AUTOSAR XML (schema 4-1-3)
standard types defined: boolean, sint8, uint16, uint32, uint8, boolean_CompuMethod, boolean_DataConstr, sint8_DataConstr, uint16_DataConstr, uint32_DataConstr, uint8_DataConstr, sint16
package /MICROSAR/Dem_swc/DataTypes
  5 x impl type:
    Dem_DebounceResetStatusType: compu {0=DEM_DEBOUNCE_STATUS_FREEZE, 1=DEM_DEBOUNCE_STATUS_RESET}, range raw 0..255, implementation-data-type=ImplementationDataTypes/uint8
    Dem_DTCFormatType: compu {0=DEM_DTC_FORMAT_OBD, 1=DEM_DTC_FORMAT_UDS, 2=DEM_DTC_FORMAT_J1939}, range raw 0..2, implementation-data-type=ImplementationDataTypes/uint8
    Dem_EventStatusType:
      compu {0=DEM_EVENT_STATUS_PASSED, 1=DEM_EVENT_STATUS_FAILED, 2=DEM_EVENT_STATUS_PREPASSED, 3=DEM_EVENT_STATUS_PREFAILED, 4=DEM_EVENT_STATUS_FDC_THRESHOLD_REACHED, 5=DEM_EVENT_STATUS_PASSED_CONDITIONS_NOT_FULFILLED, 6=DEM_EVENT_STATUS_FAILED_CONDITIONS_NOT_FULFILLED, 7=DEM_EVENT_STATUS_PREPASSED_CONDITIONS_NOT_FULFILLED, 8=DEM_EVENT_STATUS_PREFAILED_CONDITIONS_NOT_FULFILLED}
      range raw 0..255
      implementation-data-type=ImplementationDataTypes/uint8
    Dem_MaxDataValueType: category=ARRAY, sw-calibration-access=READ-ONLY
      element Dem_MaxDataValueTypeElement: array-size=40, array-size-semantics=FIXED-SIZE, implementation-data-type=ImplementationDataTypes/uint8
    Dem_UdsStatusByteType:
      compu {mask 1: 1=DEM_UDS_STATUS_TF (bit 0: TestFailed), mask 2: 2=DEM_UDS_STATUS_TFTOC (bit 1: TestFailedThisOperationCycle), mask 4: 4=DEM_UDS_STATUS_PDTC (bit 2: PendingDTC), mask 8: 8=DEM_UDS_STATUS_CDTC (bit 3: ConfirmedDTC), mask 16: 16=DEM_UDS_STATUS_TNCSLC (bit 4: TestNotCompletedSinceLastClear), mask 32: 32=DEM_UDS_STATUS_TFSLC (bit 5: TestFailedSinceLastClear), mask 64: 64=DEM_UDS_STATUS_TNCTOC (bit 6: TestNotCompletedThisOperationCycle), mask 128: 128=DEM_UDS_STATUS_WIR (bit 7: WarningIndicatorRequested)}
      range raw 0..255
      implementation-data-type=ImplementationDataTypes/uint8
package /MICROSAR/Dem_swc/Interfaces
  client server interface DiagnosticMonitor: is-service=true, service-kind=DIAGNOSTIC-EVENT-MANAGER
    11 x operation:
      GetDTCOfEvent: possible-error=[DEM_E_NO_DTC_AVAILABLE, DiagnosticMonitor/E_NOT_OK]
        arg DTCFormat: type=Dem_DTCFormatType, direction=IN, server-argument-impl-policy=USE-ARGUMENT-TYPE
        arg DTCOfEvent: type=ImplementationDataTypes/uint32, direction=OUT, server-argument-impl-policy=USE-ARGUMENT-TYPE
      GetEventExtendedDataRecordEx: possible-error=[DEM_BUFFER_TOO_SMALL, DEM_NO_SUCH_ELEMENT, DiagnosticMonitor/E_NOT_OK]
        arg RecordNumber: type=ImplementationDataTypes/uint8, direction=IN, server-argument-impl-policy=USE-ARGUMENT-TYPE
        arg DestBuffer: type=Dem_MaxDataValueType, direction=OUT, server-argument-impl-policy=USE-ARGUMENT-TYPE
        arg BufSize: type=ImplementationDataTypes/uint16, direction=INOUT, server-argument-impl-policy=USE-ARGUMENT-TYPE
      GetEventFailed: possible-error=DiagnosticMonitor/E_NOT_OK
        arg EventFailed: type=ImplementationDataTypes/boolean, direction=OUT, server-argument-impl-policy=USE-ARGUMENT-TYPE
      GetEventFreezeFrameDataEx: possible-error=[DEM_BUFFER_TOO_SMALL, DEM_NO_SUCH_ELEMENT, DiagnosticMonitor/E_NOT_OK]
        4 x arg, all with server-argument-impl-policy=USE-ARGUMENT-TYPE:
          RecordNumber: type=ImplementationDataTypes/uint8, direction=IN
          DataId: type=ImplementationDataTypes/uint16, direction=IN
          DestBuffer: type=Dem_MaxDataValueType, direction=OUT
          BufSize: type=ImplementationDataTypes/uint16, direction=INOUT
      GetEventStatus: possible-error=DiagnosticMonitor/E_NOT_OK
        arg UDSStatusByte: type=Dem_UdsStatusByteType, direction=OUT, server-argument-impl-policy=USE-ARGUMENT-TYPE
      GetEventTested: possible-error=DiagnosticMonitor/E_NOT_OK
        arg EventTested: type=ImplementationDataTypes/boolean, direction=OUT, server-argument-impl-policy=USE-ARGUMENT-TYPE
      GetEventUdsStatus: possible-error=DiagnosticMonitor/E_NOT_OK
        arg UDSStatusByte: type=Dem_UdsStatusByteType, direction=OUT, server-argument-impl-policy=USE-ARGUMENT-TYPE
      GetFaultDetectionCounter: possible-error=[DEM_E_NO_FDC_AVAILABLE, DiagnosticMonitor/E_NOT_OK]
        arg FaultDetectionCounter: type=sint8, direction=OUT, server-argument-impl-policy=USE-ARGUMENT-TYPE
      ResetEventDebounceStatus: possible-error=DiagnosticMonitor/E_NOT_OK
        arg DebounceResetStatus: type=Dem_DebounceResetStatusType, direction=IN, server-argument-impl-policy=USE-ARGUMENT-TYPE
      ResetEventStatus: possible-error=DiagnosticMonitor/E_NOT_OK
      SetEventStatus: possible-error=DiagnosticMonitor/E_NOT_OK
        arg EventStatus: type=Dem_EventStatusType, direction=IN, server-argument-impl-policy=USE-ARGUMENT-TYPE
    5 x error:
      DEM_BUFFER_TOO_SMALL: error-code=21
      DEM_E_NO_DTC_AVAILABLE: error-code=10
      DEM_E_NO_FDC_AVAILABLE: error-code=14
      DEM_NO_SUCH_ELEMENT: error-code=48
      E_NOT_OK: error-code=1
package /UAES/ASW/ApplicationDataTypes
  app type Perc_q0p0122_Perc_s16: category=VALUE, sw-calibration-access=READ-WRITE, compu {phys=raw*0.01220703125 for raw -INF..INF; unit %}, range raw -32768..32767
  app type Ti_q0p001_s_u16: category=VALUE, sw-calibration-access=READ-WRITE, compu {phys=raw*0.001}, range phys 0..65.535
  app type Ti_q1_us_u32: category=VALUE, sw-calibration-access=READ-WRITE, compu {phys=raw for raw -INF..INF; unit us}, range phys 0..4294967295, raw 0..4294967295
package /UAES/ASW/CompuMethods
  compu method CM_boolean: 0=FALSE, 1=TRUE
package /UAES/ASW/DataConstrs
  range DC_boolean: raw 0..1
  range DC_sint16: raw -32768..32767
  range DC_uint16: phys 0..6553.5, raw 0..65535
  range DC_uint32: raw 0..4294967295
  range DC_uint8: raw 0..255
package /UAES/ASW/DataTypeMappingSets
  data type mapping set DTMS_ChrgPlgLock_VD
    data-type-maps:
      application-data-type=Perc_q0p0122_Perc_s16, implementation-data-type=sint16
      application-data-type=Ti_q0p001_s_u16, implementation-data-type=ImplementationDataTypes/uint16
      application-data-type=Ti_q1_us_u32, implementation-data-type=ImplementationDataTypes/uint32
package /UAES/ASW/ImplementationDataTypes/Ground
  11 x constant specification:
    ChgrPlug_cntrTryClsng_C: value-spec=ChgrPlug_cntrTryClsng_C:10
    ChgrPlug_cntrTryOpng_C: value-spec=ChgrPlug_cntrTryOpng_C:10
    ChgrPlug_flgLockActrErr_C: value-spec=ChgrPlug_flgLockActrErr_C:0
    ChgrPlug_ratPlgLockClsng_C: value-spec=100 %
    ChgrPlug_ratPlgLockOff_C: value-spec=0 %
    ChgrPlug_ratPlgLockOpng_C: value-spec=-100 %
    ChgrPlug_tiPlgLockClsng_C: value-spec=0.5
    ChgrPlug_tiPlgLockOff_C: value-spec=0.1
    ChgrPlug_tiPlgLockOpng_C: value-spec=0.5
    ChgrPlug_tiPlgLockPwrOn_C: value-spec=0.5
    IntlckChrgPlg_tiActrPerd_C: value-spec=5000 us
package /UAES/ASW/PortInterfaces
  client server interface IoHwAb_HbrModCtrl
    operation Hbr_SetMod: possible-error=IoHwAb_HbrModCtrl/E_NOT_OK
      arg id_u16: type=ImplementationDataTypes/uint16, direction=IN, server-argument-impl-policy=USE-ARGUMENT-TYPE
      arg mod_u8: type=ImplementationDataTypes/uint8, direction=IN, server-argument-impl-policy=USE-ARGUMENT-TYPE
    error E_NOT_OK: error-code=1
  client server interface IoHwAb_HbrPwm
    operation Hbr_SetDuty: possible-error=IoHwAb_HbrPwm/E_NOT_OK
      arg id_u16: type=ImplementationDataTypes/uint16, direction=IN, server-argument-impl-policy=USE-ARGUMENT-TYPE
      arg duty_u16: type=ImplementationDataTypes/uint16, direction=IN, server-argument-impl-policy=USE-ARGUMENT-TYPE
    operation Hbr_SetPerd: possible-error=IoHwAb_HbrPwm/E_NOT_OK
      arg id_u16: type=ImplementationDataTypes/uint16, direction=IN, server-argument-impl-policy=USE-ARGUMENT-TYPE
      arg perd_u32: type=ImplementationDataTypes/uint32, direction=IN, server-argument-impl-policy=USE-ARGUMENT-TYPE
    operation Hbr_SetPerdAndDuty: possible-error=IoHwAb_HbrPwm/E_NOT_OK
      arg id_u16: type=ImplementationDataTypes/uint16, direction=IN, server-argument-impl-policy=USE-ARGUMENT-TYPE
      arg perd_u32: type=ImplementationDataTypes/uint32, direction=IN, server-argument-impl-policy=USE-ARGUMENT-TYPE
      arg duty_u16: type=ImplementationDataTypes/uint16, direction=IN, server-argument-impl-policy=USE-ARGUMENT-TYPE
    error E_NOT_OK: error-code=1
  client server interface IoHwAb_IoDiagHbr
    operation Hbr_Get: possible-error=IoHwAb_IoDiagHbr/E_NOT_OK
      arg id_u16: type=ImplementationDataTypes/uint16, direction=IN, server-argument-impl-policy=USE-ARGUMENT-TYPE
      arg val_u32: type=ImplementationDataTypes/uint32, direction=OUT, server-argument-impl-policy=USE-ARGUMENT-TYPE
    error E_NOT_OK: error-code=1
  8 x sender receiver interface:
    BattU_bVoltEnbPinDiag: invalidation-policy{data-element=BattU_bVoltEnbPinDiag/Val, handle-invalid=DONT-INVALIDATE}
      data Val: sw-calibration-access=READ-ONLY, type=ImplementationDataTypes/boolean
    ChgrPlug_stPlgLock: invalidation-policy{data-element=ChgrPlug_stPlgLock/Val, handle-invalid=DONT-INVALIDATE}
      data Val: sw-calibration-access=READ-ONLY, type=ImplementationDataTypes/uint8
    ChgrPlug_stPlgLockStMac: invalidation-policy{data-element=ChgrPlug_stPlgLockStMac/Val, handle-invalid=DONT-INVALIDATE}
      data Val: sw-calibration-access=READ-ONLY, type=ImplementationDataTypes/uint8
    ChrgPlg_stPlgLockCmd: invalidation-policy{data-element=ChrgPlg_stPlgLockCmd/Val, handle-invalid=DONT-INVALIDATE}
      data Val: sw-calibration-access=READ-ONLY, type=ImplementationDataTypes/uint8
    ChrgPlgPosn_st: invalidation-policy{data-element=ChrgPlgPosn_st/Val, handle-invalid=DONT-INVALIDATE}
      data Val: sw-calibration-access=READ-ONLY, type=ImplementationDataTypes/uint8
    IntlckChrgPlg_rActr: invalidation-policy{data-element=IntlckChrgPlg_rActr/Val, handle-invalid=DONT-INVALIDATE}
      data Val: sw-calibration-access=READ-ONLY, type=Perc_q0p0122_Perc_s16
    IntlckChrgPlg_tiActr: invalidation-policy{data-element=IntlckChrgPlg_tiActr/Val, handle-invalid=DONT-INVALIDATE}
      data Val: sw-calibration-access=READ-ONLY, type=Ti_q1_us_u32
    VehCoorn_stPwrMod: invalidation-policy{data-element=VehCoorn_stPwrMod/Val, handle-invalid=DONT-INVALIDATE}
      data Val: sw-calibration-access=READ-ONLY, type=ImplementationDataTypes/uint8
package /UAES/ASW/SwAddrMethods
  sw addr method CALDATA
package /UAES/ASW/SwComponentTypes
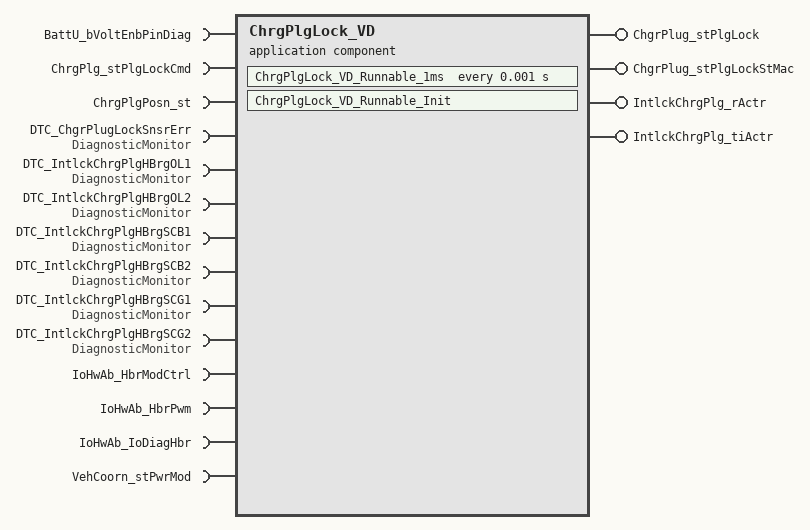
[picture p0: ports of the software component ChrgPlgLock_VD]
  application sw component type ChrgPlgLock_VD
    4 x provide port:
      ChgrPlug_stPlgLock: nonqueued-sender-com-spec{data-element=ChgrPlug_stPlgLock/Val, init-value=0}, provided-interface=ChgrPlug_stPlgLock
      ChgrPlug_stPlgLockStMac: nonqueued-sender-com-spec{data-element=ChgrPlug_stPlgLockStMac/Val, init-value=0}, provided-interface=ChgrPlug_stPlgLockStMac
      IntlckChrgPlg_rActr: nonqueued-sender-com-spec{data-element=IntlckChrgPlg_rActr/Val, init-value=0 %}, provided-interface=IntlckChrgPlg_rActr
      IntlckChrgPlg_tiActr: nonqueued-sender-com-spec{data-element=IntlckChrgPlg_tiActr/Val, init-value=0 us}, provided-interface=IntlckChrgPlg_tiActr
    14 x require port:
      BattU_bVoltEnbPinDiag: nonqueued-receiver-com-spec{data-element=BattU_bVoltEnbPinDiag/Val, filter=data-filter-type=ALWAYS, init-value=0}, required-interface=BattU_bVoltEnbPinDiag
      ChrgPlg_stPlgLockCmd: nonqueued-receiver-com-spec{data-element=ChrgPlg_stPlgLockCmd/Val, filter=data-filter-type=ALWAYS, init-value=0}, required-interface=ChrgPlg_stPlgLockCmd
      ChrgPlgPosn_st: nonqueued-receiver-com-spec{data-element=ChrgPlgPosn_st/Val, filter=data-filter-type=ALWAYS, init-value=0}, required-interface=ChrgPlgPosn_st
      DTC_ChgrPlugLockSnsrErr: required-interface=DiagnosticMonitor
        required-com-specs:
          GetDTCOfEvent
          GetEventExtendedDataRecordEx
          GetEventFailed
          GetEventFreezeFrameDataEx
          GetEventStatus
          GetEventTested
          GetEventUdsStatus
          GetFaultDetectionCounter
          ResetEventDebounceStatus
          ResetEventStatus
          SetEventStatus
      DTC_IntlckChrgPlgHBrgOL1: required-interface=DiagnosticMonitor
        required-com-specs:
          GetDTCOfEvent
          GetEventExtendedDataRecordEx
          GetEventFailed
          GetEventFreezeFrameDataEx
          GetEventStatus
          GetEventTested
          GetEventUdsStatus
          GetFaultDetectionCounter
          ResetEventDebounceStatus
          ResetEventStatus
          SetEventStatus
      DTC_IntlckChrgPlgHBrgOL2: required-interface=DiagnosticMonitor
        required-com-specs:
          GetDTCOfEvent
          GetEventExtendedDataRecordEx
          GetEventFailed
          GetEventFreezeFrameDataEx
          GetEventStatus
          GetEventTested
          GetEventUdsStatus
          GetFaultDetectionCounter
          ResetEventDebounceStatus
          ResetEventStatus
          SetEventStatus
      DTC_IntlckChrgPlgHBrgSCB1: required-interface=DiagnosticMonitor
        required-com-specs:
          GetDTCOfEvent
          GetEventExtendedDataRecordEx
          GetEventFailed
          GetEventFreezeFrameDataEx
          GetEventStatus
          GetEventTested
          GetEventUdsStatus
          GetFaultDetectionCounter
          ResetEventDebounceStatus
          ResetEventStatus
          SetEventStatus
      DTC_IntlckChrgPlgHBrgSCB2: required-interface=DiagnosticMonitor
        required-com-specs:
          GetDTCOfEvent
          GetEventExtendedDataRecordEx
          GetEventFailed
          GetEventFreezeFrameDataEx
          GetEventStatus
          GetEventTested
          GetEventUdsStatus
          GetFaultDetectionCounter
          ResetEventDebounceStatus
          ResetEventStatus
          SetEventStatus
      DTC_IntlckChrgPlgHBrgSCG1: required-interface=DiagnosticMonitor
        required-com-specs:
          GetDTCOfEvent
          GetEventExtendedDataRecordEx
          GetEventFailed
          GetEventFreezeFrameDataEx
          GetEventStatus
          GetEventTested
          GetEventUdsStatus
          GetFaultDetectionCounter
          ResetEventDebounceStatus
          ResetEventStatus
          SetEventStatus
      DTC_IntlckChrgPlgHBrgSCG2: required-interface=DiagnosticMonitor
        required-com-specs:
          GetDTCOfEvent
          GetEventExtendedDataRecordEx
          GetEventFailed
          GetEventFreezeFrameDataEx
          GetEventStatus
          GetEventTested
          GetEventUdsStatus
          GetFaultDetectionCounter
          ResetEventDebounceStatus
          ResetEventStatus
          SetEventStatus
      IoHwAb_HbrModCtrl: client-com-spec=Hbr_SetMod, required-interface=IoHwAb_HbrModCtrl
      IoHwAb_HbrPwm: required-com-specs=[Hbr_SetDuty, Hbr_SetPerd, Hbr_SetPerdAndDuty], required-interface=IoHwAb_HbrPwm
      IoHwAb_IoDiagHbr: client-com-spec=Hbr_Get, required-interface=IoHwAb_IoDiagHbr
      VehCoorn_stPwrMod: nonqueued-receiver-com-spec{data-element=VehCoorn_stPwrMod/Val, filter=data-filter-type=ALWAYS, init-value=0}, required-interface=VehCoorn_stPwrMod
    behavior ChrgPlgLock_VD_InternalBehavior: data-type-mapping=DTMS_ChrgPlgLock_VD
      timing event TMT_ChrgPlgLock_VD_Runnable_1ms: start-on-event=ChrgPlgLock_VD_Runnable_1ms, period=0.001
      init event ChrgPlgLock_VD_InitEvent: start-on-event=ChrgPlgLock_VD_Runnable_Init
      runnable ChrgPlgLock_VD_Runnable_1ms
        data-read-access:
          4 x access:
            IN_ChrgPlg_stPlgLockCmd_Val: accessed-variable=ChrgPlg_stPlgLockCmd.Val
            IN_ChrgPlgPosn_st_Val: accessed-variable=ChrgPlgPosn_st.Val
            READ_BattU_bVoltEnbPinDiag_Val: accessed-variable=BattU_bVoltEnbPinDiag.Val
            READ_VehCoorn_stPwrMod_Val: accessed-variable=VehCoorn_stPwrMod.Val
        data-write-access:
          4 x access:
            OUT_ChgrPlug_stPlgLock_Val: accessed-variable=ChgrPlug_stPlgLock.Val
            OUT_ChgrPlug_stPlgLockStMac_Val: accessed-variable=ChgrPlug_stPlgLockStMac.Val
            OUT_IntlckChrgPlg_rActr_Val: accessed-variable=IntlckChrgPlg_rActr.Val
            OUT_IntlckChrgPlg_tiActr_Val: accessed-variable=IntlckChrgPlg_tiActr.Val
        11 x parameter access:
          PA_ChgrPlug_cntrTryClsng_C: accessed-parameter=ChgrPlug_cntrTryClsng_C
          PA_ChgrPlug_cntrTryOpng_C: accessed-parameter=ChgrPlug_cntrTryOpng_C
          PA_ChgrPlug_flgLockActrErr_C: accessed-parameter=ChgrPlug_flgLockActrErr_C
          PA_ChgrPlug_ratPlgLockClsng_C: accessed-parameter=ChgrPlug_ratPlgLockClsng_C
          PA_ChgrPlug_ratPlgLockOff_C: accessed-parameter=ChgrPlug_ratPlgLockOff_C
          PA_ChgrPlug_ratPlgLockOpng_C: accessed-parameter=ChgrPlug_ratPlgLockOpng_C
          PA_ChgrPlug_tiPlgLockClsng_C: accessed-parameter=ChgrPlug_tiPlgLockClsng_C
          PA_ChgrPlug_tiPlgLockOff_C: accessed-parameter=ChgrPlug_tiPlgLockOff_C
          PA_ChgrPlug_tiPlgLockOpng_C: accessed-parameter=ChgrPlug_tiPlgLockOpng_C
          PA_ChgrPlug_tiPlgLockPwrOn_C: accessed-parameter=ChgrPlug_tiPlgLockPwrOn_C
          PA_IntlckChrgPlg_tiActrPerd_C: accessed-parameter=IntlckChrgPlg_tiActrPerd_C
        31 x sync call:
          SC_DTC_ChgrPlugLockSnsrErr_GetEventFailed: operation=DTC_ChgrPlugLockSnsrErr.GetEventFailed, timeout=1E-06
          SC_DTC_ChgrPlugLockSnsrErr_GetEventTested: operation=DTC_ChgrPlugLockSnsrErr.GetEventTested, timeout=1E-06
          SC_DTC_IntlckChrgPlgHBrgOL1_GetEventFailed: operation=DTC_IntlckChrgPlgHBrgOL1.GetEventFailed, timeout=1E-06
          SC_DTC_IntlckChrgPlgHBrgOL1_GetEventTested: operation=DTC_IntlckChrgPlgHBrgOL1.GetEventTested, timeout=1E-06
          SC_DTC_IntlckChrgPlgHBrgOL1_ResetEventDebounceStatus: operation=DTC_IntlckChrgPlgHBrgOL1.ResetEventDebounceStatus, timeout=1E-06
          SC_DTC_IntlckChrgPlgHBrgOL1_SetEventStatus: operation=DTC_IntlckChrgPlgHBrgOL1.SetEventStatus, timeout=1E-06
          SC_DTC_IntlckChrgPlgHBrgOL2_GetEventFailed: operation=DTC_IntlckChrgPlgHBrgOL2.GetEventFailed, timeout=1E-06
          SC_DTC_IntlckChrgPlgHBrgOL2_GetEventTested: operation=DTC_IntlckChrgPlgHBrgOL2.GetEventTested, timeout=1E-06
          SC_DTC_IntlckChrgPlgHBrgOL2_ResetEventDebounceStatus: operation=DTC_IntlckChrgPlgHBrgOL2.ResetEventDebounceStatus, timeout=1E-06
          SC_DTC_IntlckChrgPlgHBrgOL2_SetEventStatus: operation=DTC_IntlckChrgPlgHBrgOL2.SetEventStatus, timeout=1E-06
          SC_DTC_IntlckChrgPlgHBrgSCB1_GetEventFailed: operation=DTC_IntlckChrgPlgHBrgSCB1.GetEventFailed, timeout=1E-06
          SC_DTC_IntlckChrgPlgHBrgSCB1_GetEventTested: operation=DTC_IntlckChrgPlgHBrgSCB1.GetEventTested, timeout=1E-06
          SC_DTC_IntlckChrgPlgHBrgSCB1_ResetEventDebounceStatus: operation=DTC_IntlckChrgPlgHBrgSCB1.ResetEventDebounceStatus, timeout=1E-06
          SC_DTC_IntlckChrgPlgHBrgSCB1_SetEventStatus: operation=DTC_IntlckChrgPlgHBrgSCB1.SetEventStatus, timeout=1E-06
          SC_DTC_IntlckChrgPlgHBrgSCB2_GetEventFailed: operation=DTC_IntlckChrgPlgHBrgSCB2.GetEventFailed, timeout=1E-06
          SC_DTC_IntlckChrgPlgHBrgSCB2_GetEventTested: operation=DTC_IntlckChrgPlgHBrgSCB2.GetEventTested, timeout=1E-06
          SC_DTC_IntlckChrgPlgHBrgSCB2_ResetEventDebounceStatus: operation=DTC_IntlckChrgPlgHBrgSCB2.ResetEventDebounceStatus, timeout=1E-06
          SC_DTC_IntlckChrgPlgHBrgSCB2_SetEventStatus: operation=DTC_IntlckChrgPlgHBrgSCB2.SetEventStatus, timeout=1E-06
          SC_DTC_IntlckChrgPlgHBrgSCG1_GetEventFailed: operation=DTC_IntlckChrgPlgHBrgSCG1.GetEventFailed, timeout=1E-06
          SC_DTC_IntlckChrgPlgHBrgSCG1_GetEventTested: operation=DTC_IntlckChrgPlgHBrgSCG1.GetEventTested, timeout=1E-06
          SC_DTC_IntlckChrgPlgHBrgSCG1_ResetEventDebounceStatus: operation=DTC_IntlckChrgPlgHBrgSCG1.ResetEventDebounceStatus, timeout=1E-06
          SC_DTC_IntlckChrgPlgHBrgSCG1_SetEventStatus: operation=DTC_IntlckChrgPlgHBrgSCG1.SetEventStatus, timeout=1E-06
          SC_DTC_IntlckChrgPlgHBrgSCG2_GetEventFailed: operation=DTC_IntlckChrgPlgHBrgSCG2.GetEventFailed, timeout=1E-06
          SC_DTC_IntlckChrgPlgHBrgSCG2_GetEventTested: operation=DTC_IntlckChrgPlgHBrgSCG2.GetEventTested, timeout=1E-06
          SC_DTC_IntlckChrgPlgHBrgSCG2_ResetEventDebounceStatus: operation=DTC_IntlckChrgPlgHBrgSCG2.ResetEventDebounceStatus, timeout=1E-06
          SC_DTC_IntlckChrgPlgHBrgSCG2_SetEventStatus: operation=DTC_IntlckChrgPlgHBrgSCG2.SetEventStatus, timeout=1E-06
          SC_IoHwAb_HbrModCtrl_Hbr_SetMod: operation=IoHwAb_HbrModCtrl.Hbr_SetMod, timeout=0
          SC_IoHwAb_HbrPwm_Hbr_SetDuty: operation=IoHwAb_HbrPwm.Hbr_SetDuty, timeout=0
          SC_IoHwAb_HbrPwm_Hbr_SetPerd: operation=IoHwAb_HbrPwm.Hbr_SetPerd, timeout=0
          SC_IoHwAb_HbrPwm_Hbr_SetPerdAndDuty: operation=IoHwAb_HbrPwm.Hbr_SetPerdAndDuty, timeout=0
          SC_IoHwAb_IoDiagHbr_Hbr_Get: operation=IoHwAb_IoDiagHbr.Hbr_Get, timeout=0
      runnable ChrgPlgLock_VD_Runnable_Init
        data-write-access:
          access OUT_IntlckChrgPlg_rActr_Val: accessed-variable=IntlckChrgPlg_rActr.Val
          access OUT_IntlckChrgPlg_tiActr_Val: accessed-variable=IntlckChrgPlg_tiActr.Val
        11 x parameter access:
          PA_ChgrPlug_cntrTryClsng_C: accessed-parameter=ChgrPlug_cntrTryClsng_C
          PA_ChgrPlug_cntrTryOpng_C: accessed-parameter=ChgrPlug_cntrTryOpng_C
          PA_ChgrPlug_flgLockActrErr_C: accessed-parameter=ChgrPlug_flgLockActrErr_C
          PA_ChgrPlug_ratPlgLockClsng_C: accessed-parameter=ChgrPlug_ratPlgLockClsng_C
          PA_ChgrPlug_ratPlgLockOff_C: accessed-parameter=ChgrPlug_ratPlgLockOff_C
          PA_ChgrPlug_ratPlgLockOpng_C: accessed-parameter=ChgrPlug_ratPlgLockOpng_C
          PA_ChgrPlug_tiPlgLockClsng_C: accessed-parameter=ChgrPlug_tiPlgLockClsng_C
          PA_ChgrPlug_tiPlgLockOff_C: accessed-parameter=ChgrPlug_tiPlgLockOff_C
          PA_ChgrPlug_tiPlgLockOpng_C: accessed-parameter=ChgrPlug_tiPlgLockOpng_C
          PA_ChgrPlug_tiPlgLockPwrOn_C: accessed-parameter=ChgrPlug_tiPlgLockPwrOn_C
          PA_IntlckChrgPlg_tiActrPerd_C: accessed-parameter=IntlckChrgPlg_tiActrPerd_C
      shared-parameters:
        11 x parameter data prototype, all with sw-addr-method=CALDATA, sw-calibration-access=READ-WRITE:
          ChgrPlug_cntrTryClsng_C: type=ImplementationDataTypes/uint8, init-value=constant-reference={short-label=ChgrPlug_cntrTryClsng_C, constant=ChgrPlug_cntrTryClsng_C}
          ChgrPlug_cntrTryOpng_C: type=ImplementationDataTypes/uint8, init-value=constant-reference={short-label=ChgrPlug_cntrTryOpng_C, constant=ChgrPlug_cntrTryOpng_C}
          ChgrPlug_flgLockActrErr_C: type=ImplementationDataTypes/boolean, init-value=constant-reference={short-label=ChgrPlug_flgLockActrErr_C, constant=ChgrPlug_flgLockActrErr_C}
          ChgrPlug_ratPlgLockClsng_C: type=Perc_q0p0122_Perc_s16, init-value=constant-reference={short-label=ChgrPlug_ratPlgLockClsng_C, constant=ChgrPlug_ratPlgLockClsng_C}
          ChgrPlug_ratPlgLockOff_C: type=Perc_q0p0122_Perc_s16, init-value=constant-reference={short-label=ChgrPlug_ratPlgLockOff_C, constant=ChgrPlug_ratPlgLockOff_C}
          ChgrPlug_ratPlgLockOpng_C: type=Perc_q0p0122_Perc_s16, init-value=constant-reference={short-label=ChgrPlug_ratPlgLockOpng_C, constant=ChgrPlug_ratPlgLockOpng_C}
          ChgrPlug_tiPlgLockClsng_C: type=Ti_q0p001_s_u16, init-value=constant-reference={short-label=ChgrPlug_tiPlgLockClsng_C, constant=ChgrPlug_tiPlgLockClsng_C}
          ChgrPlug_tiPlgLockOff_C: type=Ti_q0p001_s_u16, init-value=constant-reference={short-label=ChgrPlug_tiPlgLockOff_C, constant=ChgrPlug_tiPlgLockOff_C}
          ChgrPlug_tiPlgLockOpng_C: type=Ti_q0p001_s_u16, init-value=constant-reference={short-label=ChgrPlug_tiPlgLockOpng_C, constant=ChgrPlug_tiPlgLockOpng_C}
          ChgrPlug_tiPlgLockPwrOn_C: type=Ti_q0p001_s_u16, init-value=constant-reference={short-label=ChgrPlug_tiPlgLockPwrOn_C, constant=ChgrPlug_tiPlgLockPwrOn_C}
          IntlckChrgPlg_tiActrPerd_C: type=Ti_q1_us_u32, init-value=constant-reference={short-label=IntlckChrgPlg_tiActrPerd_C, constant=IntlckChrgPlg_tiActrPerd_C}
  swc implementation ChrgPlgLock_VD_imp: behavior=ChrgPlgLock_VD_InternalBehavior
    code-descriptors:
      code Default: artifact-descriptors=autosar-engineering-object={short-label=Default, category=SWSRC}
package /UAES/ASW/Units
  unit NoUnit: factor-si-to-unit=1, offset-si-to-unit=0
  unit Perc: display-name=%, factor-si-to-unit=1, offset-si-to-unit=0
  unit us: display-name=us, factor-si-to-unit=1, offset-si-to-unit=0
